# NPCX498S register map
File version: 1.0
Registers are 8-bit, read-write, reset 0x0 unless marked. A register's access mark holds for its fields unless they carry their own. Offsets are from the block's base; [hi:lo] are bit positions; {n}, {i} and the like mark numbered series; 'fields as' and 'values as' point back to an identical list.

## SHM
Base 0x40010000
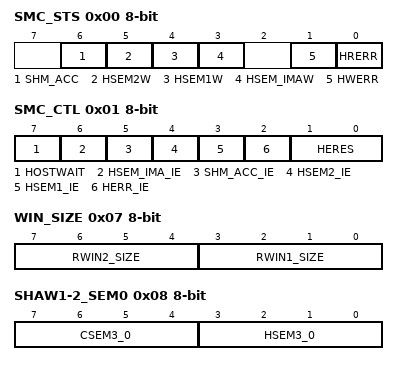
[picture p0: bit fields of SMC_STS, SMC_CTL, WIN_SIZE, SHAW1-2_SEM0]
0x00 SMC_STS — Shared Memory Core Status Register (SMC_STS)
  [6] SHM_ACC — Host Access to Shared Memory
  [5] HSEM2W — Host Semaphore 2 Written
  [4] HSEM1W — Host Semaphore 1 Written
  [3] HSEM_IMAW — Host Semaphore Indirect Memory Access Written
  [1] HWERR — Host Write Access Error
  [0] HRERR — Host Read Access Error
0x01 SMC_CTL — Shared Memory Core Control Register (SMC_CTL)
  [7] HOSTWAIT — Host Access Stall
  [6] HSEM_IMA_IE — Enable Interrupt by Host Indirect Memory Access Written
  [5] SHM_ACC_IE — Enable Interrupt by Host Access to Shared Memory
  [4] HSEM2_IE — Enable Interrupt by Host Semaphore 2 Written
  [3] HSEM1_IE — Enable Interrupt by Host Semaphore 1 Written
  [2] HERR_IE — Enable Interrupt by Host Access Errors
  [1:0] HERES — Host Error Response
0x02 SHM_CTL — Shared Memory Control Register (SHM_CTL)
  [6] STALL_HOST — Stall Host Access to Shared Memory
0x05 IMA_WIN_SIZE — Indirect Memory Access Window Size Register (IMA_WIN_SIZE)
  [3:0] IMA_SIZE — Indirect Memory Access Size Select
0x07 WIN_SIZE — Shared Access Windows Size Register (WIN_SIZE)
  [7:4] RWIN2_SIZE — RAM Access Window 2, Size Select
  [3:0] RWIN1_SIZE — RAM Access Window 1, Size Select
0x08 SHAW1-2_SEM0 — Shared Access Window 1-2, Semaphore Register (SHAW1-2_SEM)
  [7:4] CSEM3_0 — Core Semaphore Bits 3-0
  [3:0] HSEM3_0 — Host Semaphore Bits 3-0
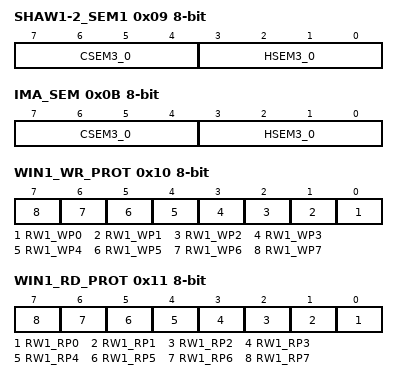
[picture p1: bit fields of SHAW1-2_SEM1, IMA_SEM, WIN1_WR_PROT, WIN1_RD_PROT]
0x09 SHAW1-2_SEM1 — Shared Access Window 1-2, Semaphore Register (SHAW1-2_SEM)
  fields as SHAW1-2_SEM0
0x0B IMA_SEM — Indirect Memory Access, Semaphore Register (IMA_SEM)
  fields as SHAW1-2_SEM0
0x0E SHCFG 16-bit — Shared Memory Configuration Register (SHCFG)
  [0] IMAEN — Indirect Memory Access Enable
0x10 WIN1_WR_PROT — Shared Access Window 1 Write Protect Register (WIN1_WR_PROT)
  [n] RW1_WP{n} (n=0..7) — RAM Access Window 1 Write Protect {n}
0x11 WIN1_RD_PROT — Shared Access Window 1 Read Protect Register (WIN1_RD_PROT)
  [n] RW1_RP{n} (n=0..7) — RAM Access Window 1 Read Protect {n}
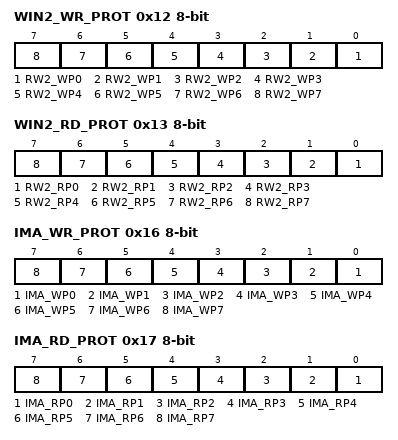
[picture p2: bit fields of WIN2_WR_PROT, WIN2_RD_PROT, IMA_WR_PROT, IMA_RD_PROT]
0x12 WIN2_WR_PROT — Shared Access Window 2 Write Protect Register (WIN2_WR_PROT)
  [n] RW2_WP{n} (n=0..7) — RAM Access Window 2 Write Protect {n}
0x13 WIN2_RD_PROT — Shared Access Window 2 Read Protect Register (WIN2_RD_PROT)
  [n] RW2_RP{n} (n=0..7) — RAM Access Window 2 Read Protect {n}
0x16 IMA_WR_PROT — Indirect Memory Access Write Protect Register (IMA_WR_PROT)
  [n] IMA_WP{n} (n=0..7) — RAM Access Window 2 Write Protect {n}
0x17 IMA_RD_PROT — Indirect Memory Access Read Protect Register (IMA_RD_PROT)
  [n] IMA_RP{n} (n=0..7) — RAM Access Window 2 Read Protect {n}
0x20 WIN_BASE1 32-bit (reset mask 0xFF) — Shared Access Window 1 Base Register (WIN_BASE1)
0x24 WIN_BASE2 32-bit (reset mask 0xFF) — Shared Access Window 2 Base Register (WIN_BASE2)
0x2C IMA_BASE 32-bit (reset mask 0xFF) — Indirect Memory Access Window Base Register (IMA_BASE)
0x3A RST_CFG — Reset Configuration Register (RST_CFG)
  [7] LRESET_PLTRST_DIS — LRESET or PLTRST Disable
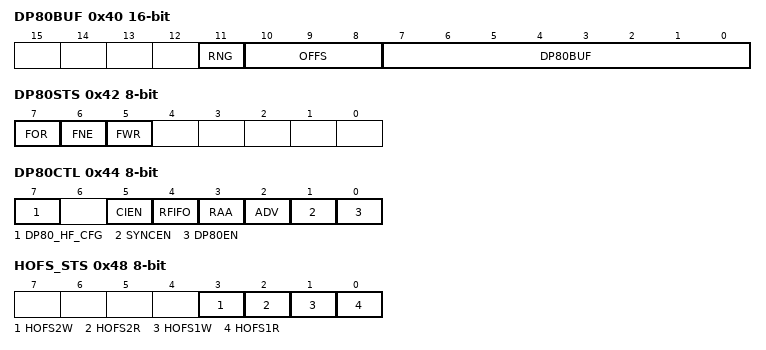
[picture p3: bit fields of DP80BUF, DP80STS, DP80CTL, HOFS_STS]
0x40 DP80BUF 16-bit (reset mask 0xFF) — Debug Port 80 Buffered Data Register (DP80BUF)
  [11] RNG — Address Range
  [10:8] OFFS — Offset Address
  [7:0] DP80BUF — Debug Port 80 Buffered Data
0x42 DP80STS — Debug Port 80 Status Register (DP80STS)
  [7] FOR — FIFO Overrun
  [6] FNE — FIFO Not Empty
  [5] FWR — FIFO Was Written
0x44 DP80CTL — Debug Port 80 Control Register (DP80CTL)
  [7] DP80_HF_CFG — Debug Port 80 Configure for High-Frequency Clock
  [5] CIEN — Core Interrupt Enable
  [4] RFIFO — Reset FIFO
  [3] RAA — Read Auto Advance
  [2] ADV — Read Advance
  [1] SYNCEN — Enable LPC SYNC
  [0] DP80EN — Debug Port 80 Enable
0x48 HOFS_STS — Host_Offset in Windows 1,2 Status Register (HOFS_STS)
  [3] HOFS2W — Host Write to Offset in Window 2 Status
  [2] HOFS2R — Host Read from Offset in Window 2 Status
  [1] HOFS1W — Host Write to Offset in Window 1 Status
  [0] HOFS1R — Host Read from Offset in Window 1 Status
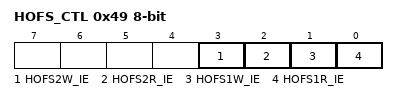
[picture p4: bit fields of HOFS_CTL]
0x49 HOFS_CTL — Host_Offset in Windows 1,2 Control Register (HOFS_CTL)
  [3] HOFS2W_IE — Enable Interrupt by Host Write to Offset in Window 2
  [2] HOFS2R_IE — Enable Interrupt by Host Read to Offset in Window 2
  [1] HOFS1W_IE — Enable Interrupt by Host Write to Offset in Window 1
  [0] HOFS1R_IE — Enable Interrupt by Host Read to Offset in Window 1
0x4A COFS2 16-bit (reset mask 0xFF) — Core_Offset in Window 2 Address Register (COFS2)
  [11:0] COFS2_DAT — Core_Offset in Window 2, Data
0x4C COFS1 16-bit (reset mask 0xFF) — Core_Offset in Window 1 Address Register (COFS1)
  [11:0] COFS1_DAT — Core Offset in Window 1, Data
